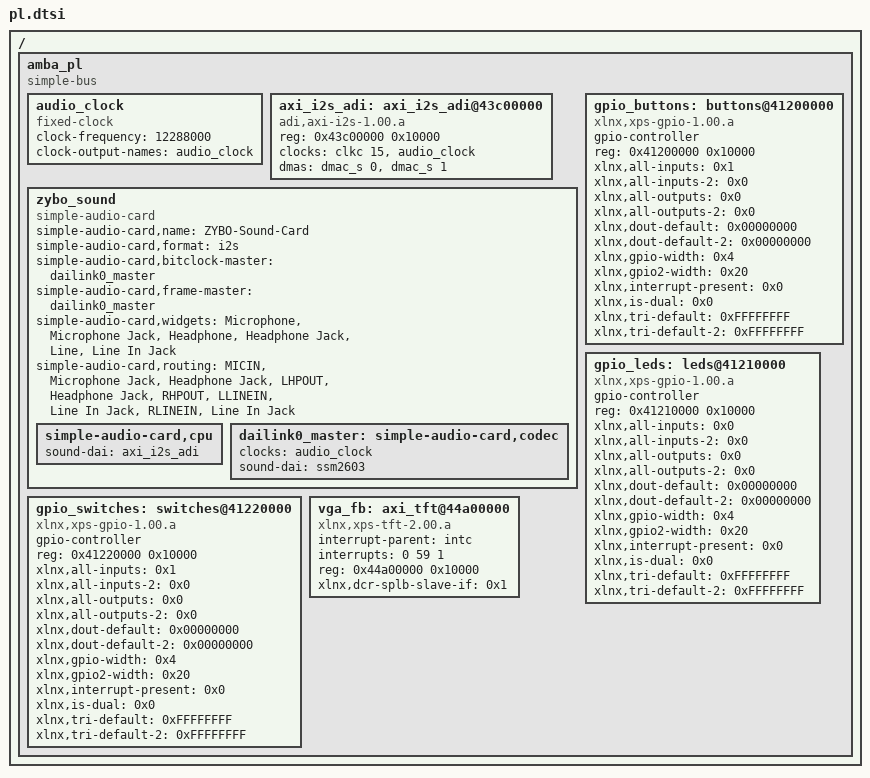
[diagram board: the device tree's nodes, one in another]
/*
 * CAUTION: This file is automatically generated by Xilinx.
 * Version:  
 * Today is: Sat Jul 29 10:51:53 2017
*/


/ {
	amba_pl: amba_pl {
		#address-cells = <1>;
		#size-cells = <1>;
		compatible = "simple-bus";
		ranges ;
		audio_clock: audio_clock {
			compatible = "fixed-clock";
			#clock-cells = <0>;
			clock-frequency = <12288000>;
			clock-output-names = "audio_clock";
		};
		axi_i2s_adi: axi_i2s_adi@43c00000 {
			#sound-dai-cells = <0>;
			compatible = "adi,axi-i2s-1.00.a";
			reg = <0x43c00000 0x10000>;
			clocks = <&clkc 15>, <&audio_clock>;
			clock-names = "axi", "ref";
			dmas = <&dmac_s 0 &dmac_s 1>;
			dma-names = "tx", "rx";
		};
		zybo_sound: zybo_sound {
				compatible = "simple-audio-card";
				simple-audio-card,name = "ZYBO-Sound-Card";
				simple-audio-card,format = "i2s";
				simple-audio-card,bitclock-master = <&dailink0_master>;
				simple-audio-card,frame-master = <&dailink0_master>;
				simple-audio-card,widgets =
            "Microphone", "Microphone Jack",
            "Headphone", "Headphone Jack",
            "Line", "Line In Jack";
         simple-audio-card,routing =
            "MICIN", "Microphone Jack",
            "Headphone Jack", "LHPOUT",
            "Headphone Jack", "RHPOUT",
            "LLINEIN", "Line In Jack",
            "RLINEIN", "Line In Jack";
						
				simple-audio-card,cpu {
					sound-dai = <&axi_i2s_adi>;
				};

				dailink0_master: simple-audio-card,codec {
					clocks = <&audio_clock>;
 					sound-dai = <&ssm2603>;
				};
		};
		gpio_buttons: buttons@41200000 {
			#gpio-cells = <2>;
			compatible = "xlnx,xps-gpio-1.00.a";
			gpio-controller ;
			reg = <0x41200000 0x10000>;
			xlnx,all-inputs = <0x1>;
			xlnx,all-inputs-2 = <0x0>;
			xlnx,all-outputs = <0x0>;
			xlnx,all-outputs-2 = <0x0>;
			xlnx,dout-default = <0x00000000>;
 			xlnx,dout-default-2 = <0x00000000>;
			xlnx,gpio-width = <0x4>;
			xlnx,gpio2-width = <0x20>;
			xlnx,interrupt-present = <0x0>;
			xlnx,is-dual = <0x0>;
			xlnx,tri-default = <0xFFFFFFFF>;
			xlnx,tri-default-2 = <0xFFFFFFFF>;
		};

		gpio_leds: leds@41210000 {
			#gpio-cells = <2>;
			compatible = "xlnx,xps-gpio-1.00.a";
			gpio-controller ;
			reg = <0x41210000 0x10000>;
			xlnx,all-inputs = <0x0>;
			xlnx,all-inputs-2 = <0x0>;
			xlnx,all-outputs = <0x0>;
			xlnx,all-outputs-2 = <0x0>;
			xlnx,dout-default = <0x00000000>;
			xlnx,dout-default-2 = <0x00000000>;
			xlnx,gpio-width = <0x4>;
			xlnx,gpio2-width = <0x20>;
			xlnx,interrupt-present = <0x0>;
			xlnx,is-dual = <0x0>;
			xlnx,tri-default = <0xFFFFFFFF>;
			xlnx,tri-default-2 = <0xFFFFFFFF>;
		};
		gpio_switches: switches@41220000 {
			#gpio-cells = <2>;
			compatible = "xlnx,xps-gpio-1.00.a";
			gpio-controller ;
			reg = <0x41220000 0x10000>;
			xlnx,all-inputs = <0x1>;
			xlnx,all-inputs-2 = <0x0>;
			xlnx,all-outputs = <0x0>;
			xlnx,all-outputs-2 = <0x0>;
			xlnx,dout-default = <0x00000000>;
			xlnx,dout-default-2 = <0x00000000>;
			xlnx,gpio-width = <0x4>;
			xlnx,gpio2-width = <0x20>;
			xlnx,interrupt-present = <0x0>;
			xlnx,is-dual = <0x0>;
			xlnx,tri-default = <0xFFFFFFFF>;
			xlnx,tri-default-2 = <0xFFFFFFFF>;
		};
		vga_fb: axi_tft@44a00000 {
			compatible = "xlnx,xps-tft-2.00.a";
			interrupt-parent = <&intc>;
			interrupts = <0 59 1>;
			reg = <0x44a00000 0x10000>;
			xlnx,dcr-splb-slave-if = <0x1>;
		};
	};
};
